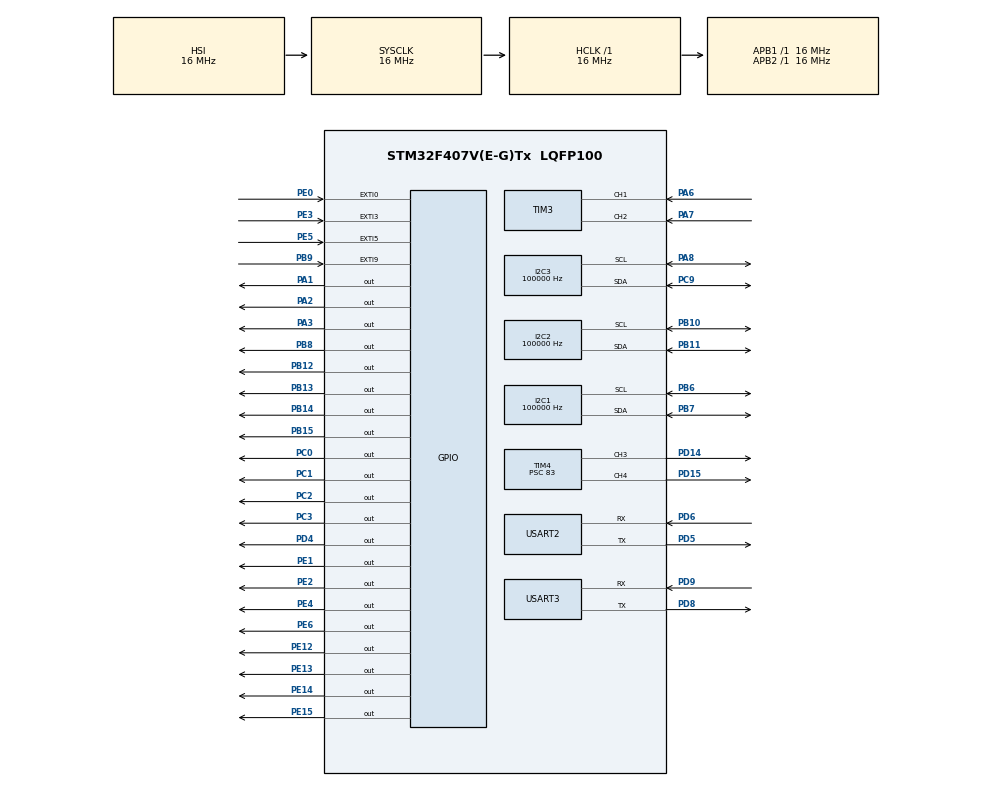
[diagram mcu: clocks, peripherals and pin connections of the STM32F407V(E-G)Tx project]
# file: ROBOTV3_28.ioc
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Dma.Request0=USART3_RX
Dma.Request1=USART3_TX
Dma.USART3_RX.0.Direction=DMA_PERIPH_TO_MEMORY
Dma.USART3_RX.0.FIFOMode=DMA_FIFOMODE_DISABLE
Dma.USART3_RX.0.Instance=DMA1_Stream1
Dma.USART3_RX.0.MemDataAlignment=DMA_MDATAALIGN_BYTE
Dma.USART3_RX.0.MemInc=DMA_MINC_ENABLE
Dma.USART3_RX.0.Mode=DMA_NORMAL
Dma.USART3_RX.0.PeriphDataAlignment=DMA_PDATAALIGN_BYTE
Dma.USART3_RX.0.PeriphInc=DMA_PINC_DISABLE
Dma.USART3_RX.0.Priority=DMA_PRIORITY_LOW
Dma.USART3_TX.1.Direction=DMA_MEMORY_TO_PERIPH
Dma.USART3_TX.1.FIFOMode=DMA_FIFOMODE_DISABLE
Dma.USART3_TX.1.Instance=DMA1_Stream4
Dma.USART3_TX.1.MemDataAlignment=DMA_MDATAALIGN_BYTE
Dma.USART3_TX.1.MemInc=DMA_MINC_ENABLE
Dma.USART3_TX.1.Mode=DMA_NORMAL
Dma.USART3_TX.1.PeriphDataAlignment=DMA_PDATAALIGN_BYTE
Dma.USART3_TX.1.PeriphInc=DMA_PINC_DISABLE
Dma.USART3_TX.1.Priority=DMA_PRIORITY_LOW
FREERTOS.BinarySemaphores01=Seme_Tx_dwin,Dynamic,NULL,Available;Theta_xyz,Dynamic,NULL,Available
FREERTOS.Queues01=Queue_DWIN,37,uint8_t,0,Dynamic,NULL,NULL
FREERTOS.Tasks01=Sensor_Task,24,128,Sensor_AS5600,Default,NULL,Dynamic,NULL,NULL;TaskHmi,8,128,Dwin_Task,Default,NULL,Dynamic,NULL,NULL;Task_DMA_HMI,25,128,TASK_DMA_ENTRY,Default,NULL,Dynamic,NULL,NULL;Task_controlmot,17,128,StartTask05,Default,NULL,Dynamic,NULL,NULL;Task_Dwin_get_t,26,128,StartTask06,Default,NULL,Dynamic,NULL,NULL
I2C1.ClockSpeed=100000
I2C1.I2C_Mode=I2C_Standard
I2C2.ClockSpeed=100000
I2C2.I2C_Mode=I2C_Standard
I2C3.ClockSpeed=100000
I2C3.I2C_Mode=I2C_Standard
Mcu.Family=STM32F4
Mcu.Name=STM32F407V(E-G)Tx
Mcu.Package=LQFP100
NVIC.DMA1_Stream1_IRQn=true\:5\:0\:false\:false\:true\:true\:false\:true\:true
NVIC.DMA1_Stream4_IRQn=true\:5\:0\:false\:false\:true\:true\:false\:true\:true
NVIC.EXTI9_5_IRQn=true\:7\:0\:true\:false\:true\:true\:true\:true\:true
NVIC.PriorityGroup=NVIC_PRIORITYGROUP_4
NVIC.TIM2_IRQn=true\:5\:0\:false\:false\:true\:true\:true\:true\:true
NVIC.TIM7_IRQn=true\:15\:0\:false\:false\:true\:false\:false\:true\:true
NVIC.TimeBase=TIM7_IRQn
NVIC.TimeBaseIP=TIM7
NVIC.USART3_IRQn=true\:5\:0\:true\:false\:true\:true\:true\:true\:true
PA1.GPIO_Speed=GPIO_SPEED_FREQ_VERY_HIGH
PA1.Signal=GPIO_Output
PA13.Mode=Serial_Wire
PA13.Signal=SYS_JTMS-SWDIO
PA14.Mode=Serial_Wire
PA14.Signal=SYS_JTCK-SWCLK
PA2.GPIO_Speed=GPIO_SPEED_FREQ_VERY_HIGH
PA2.Signal=GPIO_Output
PA3.GPIO_Speed=GPIO_SPEED_FREQ_VERY_HIGH
PA3.Signal=GPIO_Output
PA6.Signal=S_TIM3_CH1
PA7.Signal=S_TIM3_CH2
PA8.Mode=I2C
PA8.Signal=I2C3_SCL
PB10.Mode=I2C
PB10.Signal=I2C2_SCL
PB11.Mode=I2C
PB11.Signal=I2C2_SDA
PB12.Signal=GPIO_Output
PB13.Signal=GPIO_Output
PB14.Signal=GPIO_Output
PB15.Signal=GPIO_Output
PB6.Mode=I2C
PB6.Signal=I2C1_SCL
PB7.Mode=I2C
PB7.Signal=I2C1_SDA
PB8.Signal=GPIO_Output
PB9.GPIO_ModeDefaultEXTI=GPIO_MODE_IT_FALLING
PB9.Signal=GPXTI9
PC0.Signal=GPIO_Output
PC1.Signal=GPIO_Output
PC2.Signal=GPIO_Output
PC3.Signal=GPIO_Output
PC9.Mode=I2C
PC9.Signal=I2C3_SDA
PD14.Signal=S_TIM4_CH3
PD15.Signal=S_TIM4_CH4
PD4.Signal=GPIO_Output
PD5.Mode=Asynchronous
PD5.Signal=USART2_TX
PD6.Mode=Asynchronous
PD6.Signal=USART2_RX
PD8.Mode=Asynchronous
PD8.Signal=USART3_TX
PD9.Mode=Asynchronous
PD9.Signal=USART3_RX
PE0.GPIO_ModeDefaultEXTI=GPIO_MODE_IT_FALLING
PE0.Signal=GPXTI0
PE1.Signal=GPIO_Output
PE12.Signal=GPIO_Output
PE13.Signal=GPIO_Output
PE14.Signal=GPIO_Output
PE15.Signal=GPIO_Output
PE2.Signal=GPIO_Output
PE3.GPIO_ModeDefaultEXTI=GPIO_MODE_IT_FALLING
PE3.Signal=GPXTI3
PE4.Signal=GPIO_Output
PE5.GPIO_ModeDefaultEXTI=GPIO_MODE_IT_FALLING
PE5.Signal=GPXTI5
PE6.Signal=GPIO_Output
PH0-OSC_IN.Mode=HSE-External-Oscillator
PH0-OSC_IN.Signal=RCC_OSC_IN
PH1-OSC_OUT.Mode=HSE-External-Oscillator
PH1-OSC_OUT.Signal=RCC_OSC_OUT
ProjectManager.HeapSize=0x200
ProjectManager.StackSize=0x400
ProjectManager.TargetToolchain=STM32CubeIDE
RCC.AHBFreq_Value=16000000
RCC.APB1Freq_Value=16000000
RCC.APB2Freq_Value=16000000
RCC.CortexFreq_Value=16000000
RCC.HSE_VALUE=25000000
RCC.HSI_VALUE=16000000
RCC.LSE_VALUE=32768
RCC.SYSCLKFreq_VALUE=16000000
RCC.VCOOutputFreq_Value=192000000
SH.S_TIM3_CH1.0=TIM3_CH1,Encoder_Interface
SH.S_TIM3_CH2.0=TIM3_CH2,Encoder_Interface
SH.S_TIM4_CH3.0=TIM4_CH3,PWM Generation3 CH3
SH.S_TIM4_CH4.0=TIM4_CH4,PWM Generation4 CH4
TIM2.Period=99
TIM2.Prescaler=83
TIM4.Channel-PWM\ Generation3\ CH3=TIM_CHANNEL_3
TIM4.Channel-PWM\ Generation4\ CH4=TIM_CHANNEL_4
TIM4.Period=99
TIM4.Prescaler=83
USART2.VirtualMode=VM_ASYNC
USART3.VirtualMode=VM_ASYNC
VP_FREERTOS_VS_CMSIS_V2.Mode=CMSIS_V2
VP_SYS_VS_tim7.Mode=TIM7
VP_TIM2_VS_ClockSourceINT.Mode=Internal
board=custom

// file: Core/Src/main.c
/* USER CODE BEGIN Header */
/**
  ******************************************************************************
  * @file           : main.c
  * @brief          : Main program body
  ******************************************************************************
  * @attention
  *
  * Copyright (c) 2025 STMicroelectronics.
  * All rights reserved.
  *
  * This software is licensed under terms that can be found in the LICENSE file
  * in the root directory of this software component.
  * If no LICENSE file comes with this software, it is provided AS-IS.
  *
  ******************************************************************************
  */
/* USER CODE END Header */
#include "main.h"
#include "cmsis_os.h"
#include "dma.h"
#include "i2c.h"
#include "tim.h"
#include "usart.h"
#include "gpio.h"

/* USER CODE BEGIN Includes */
#include "alt_main.h"
/* USER CODE END Includes */

void SystemClock_Config(void);
void MX_FREERTOS_Init(void);

int main(void)
{

  /* MCU Configuration--------------------------------------------------------*/

  /* Reset of all peripherals, Initializes the Flash interface and the Systick. */
  HAL_Init();

  /* Configure the system clock */
  SystemClock_Config();

  /* USER CODE BEGIN SysInit */
  HAL_Delay(3000);//ỔN ĐỊNH MÀN HÌNH
  /* USER CODE END SysInit */

  /* Initialize all configured peripherals */
  MX_GPIO_Init();
  MX_DMA_Init();
  MX_I2C1_Init();
  MX_I2C2_Init();
  MX_I2C3_Init();
  MX_USART3_UART_Init();
  MX_TIM2_Init();
  MX_TIM4_Init();
  MX_USART2_UART_Init();
  MX_TIM3_Init();
  /* USER CODE BEGIN 2 */
  alt_main();
  /* USER CODE END 2 */

  /* Init scheduler */
  osKernelInitialize();

  /* Call init function for freertos objects (in cmsis_os2.c) */
  MX_FREERTOS_Init();

  /* Start scheduler */
  osKernelStart();

  /* We should never get here as control is now taken by the scheduler */

  /* Infinite loop */
  while (1)
  {

  }
}

void SystemClock_Config(void)
{
  RCC_OscInitTypeDef RCC_OscInitStruct = {0};
  RCC_ClkInitTypeDef RCC_ClkInitStruct = {0};

  /** Configure the main internal regulator output voltage
  */
  __HAL_RCC_PWR_CLK_ENABLE();
  __HAL_PWR_VOLTAGESCALING_CONFIG(PWR_REGULATOR_VOLTAGE_SCALE1);

  /** Initializes the RCC Oscillators according to the specified parameters
  * in the RCC_OscInitTypeDef structure.
  */
  RCC_OscInitStruct.OscillatorType = RCC_OSCILLATORTYPE_HSI;
  RCC_OscInitStruct.HSIState = RCC_HSI_ON;
  RCC_OscInitStruct.HSICalibrationValue = RCC_HSICALIBRATION_DEFAULT;
  RCC_OscInitStruct.PLL.PLLState = RCC_PLL_NONE;
  if (HAL_RCC_OscConfig(&RCC_OscInitStruct) != HAL_OK)
  {
    Error_Handler();
  }

  /** Initializes the CPU, AHB and APB buses clocks
  */
  RCC_ClkInitStruct.ClockType = RCC_CLOCKTYPE_HCLK|RCC_CLOCKTYPE_SYSCLK
                              |RCC_CLOCKTYPE_PCLK1|RCC_CLOCKTYPE_PCLK2;
  RCC_ClkInitStruct.SYSCLKSource = RCC_SYSCLKSOURCE_HSI;
  RCC_ClkInitStruct.AHBCLKDivider = RCC_SYSCLK_DIV1;
  RCC_ClkInitStruct.APB1CLKDivider = RCC_HCLK_DIV1;
  RCC_ClkInitStruct.APB2CLKDivider = RCC_HCLK_DIV1;

  if (HAL_RCC_ClockConfig(&RCC_ClkInitStruct, FLASH_LATENCY_0) != HAL_OK)
  {
    Error_Handler();
  }
}

void HAL_TIM_PeriodElapsedCallback(TIM_HandleTypeDef *htim)
{
  if (htim->Instance == TIM7) {
    HAL_IncTick();
  }
  /* USER CODE BEGIN Callback 1 */
  if (htim->Instance == TIM2){
	  TIM2_CALLBACK_STEP();
  }
  /* USER CODE END Callback 1 */
}

void Error_Handler(void)
{
  __disable_irq();
  while (1)
  {
  }
}

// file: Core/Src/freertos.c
/* USER CODE BEGIN Header */
/**
  ******************************************************************************
  * File Name          : freertos.c
  * Description        : Code for freertos applications
  ******************************************************************************
  * @attention
  *
  * Copyright (c) 2025 STMicroelectronics.
  * All rights reserved.
  *
  * This software is licensed under terms that can be found in the LICENSE file
  * in the root directory of this software component.
  * If no LICENSE file comes with this software, it is provided AS-IS.
  *
  ******************************************************************************
  */
/* USER CODE END Header */

#include "FreeRTOS.h"
#include "task.h"
#include "main.h"
#include "cmsis_os.h"

/* USER CODE BEGIN Includes */
#include "alt_main.h"
/* USER CODE END Includes */

/* Definitions for Sensor_Task */
osThreadId_t Sensor_TaskHandle;
const osThreadAttr_t Sensor_Task_attributes = {
  .name = "Sensor_Task",
  .stack_size = 128 * 4,
  .priority = (osPriority_t) osPriorityNormal,
};
/* Definitions for TaskHmi */
osThreadId_t TaskHmiHandle;
const osThreadAttr_t TaskHmi_attributes = {
  .name = "TaskHmi",
  .stack_size = 128 * 4,
  .priority = (osPriority_t) osPriorityLow,
};
/* Definitions for Task_DMA_HMI */
osThreadId_t Task_DMA_HMIHandle;
const osThreadAttr_t Task_DMA_HMI_attributes = {
  .name = "Task_DMA_HMI",
  .stack_size = 128 * 4,
  .priority = (osPriority_t) osPriorityNormal1,
};
/* Definitions for Task_controlmot */
osThreadId_t Task_controlmotHandle;
const osThreadAttr_t Task_controlmot_attributes = {
  .name = "Task_controlmot",
  .stack_size = 128 * 4,
  .priority = (osPriority_t) osPriorityBelowNormal1,
};
/* Definitions for Task_Dwin_get_t */
osThreadId_t Task_Dwin_get_tHandle;
const osThreadAttr_t Task_Dwin_get_t_attributes = {
  .name = "Task_Dwin_get_t",
  .stack_size = 128 * 4,
  .priority = (osPriority_t) osPriorityNormal2,
};
/* Definitions for Queue_DWIN */
osMessageQueueId_t Queue_DWINHandle;
const osMessageQueueAttr_t Queue_DWIN_attributes = {
  .name = "Queue_DWIN"
};
/* Definitions for Seme_Tx_dwin */
osSemaphoreId_t Seme_Tx_dwinHandle;
const osSemaphoreAttr_t Seme_Tx_dwin_attributes = {
  .name = "Seme_Tx_dwin"
};
/* Definitions for Theta_xyz */
osSemaphoreId_t Theta_xyzHandle;
const osSemaphoreAttr_t Theta_xyz_attributes = {
  .name = "Theta_xyz"
};

void Sensor_AS5600(void *argument);
void Dwin_Task(void *argument);
void TASK_DMA_ENTRY(void *argument);
void StartTask05(void *argument);
void StartTask06(void *argument);

void MX_FREERTOS_Init(void); /* (MISRA C 2004 rule 8.1) */

void MX_FREERTOS_Init(void) {

  /* Create the semaphores(s) */
  /* creation of Seme_Tx_dwin */
  Seme_Tx_dwinHandle = osSemaphoreNew(1, 1, &Seme_Tx_dwin_attributes);

  /* creation of Theta_xyz */
  Theta_xyzHandle = osSemaphoreNew(1, 0, &Theta_xyz_attributes);

  /* Create the queue(s) */
  /* creation of Queue_DWIN */
  Queue_DWINHandle = osMessageQueueNew (37, sizeof(uint8_t), &Queue_DWIN_attributes);

  /* Create the thread(s) */
  /* creation of Sensor_Task */
  Sensor_TaskHandle = osThreadNew(Sensor_AS5600, NULL, &Sensor_Task_attributes);

  /* creation of TaskHmi */
  TaskHmiHandle = osThreadNew(Dwin_Task, NULL, &TaskHmi_attributes);

  /* creation of Task_DMA_HMI */
  Task_DMA_HMIHandle = osThreadNew(TASK_DMA_ENTRY, NULL, &Task_DMA_HMI_attributes);

  /* creation of Task_controlmot */
  Task_controlmotHandle = osThreadNew(StartTask05, NULL, &Task_controlmot_attributes);

  /* creation of Task_Dwin_get_t */
  Task_Dwin_get_tHandle = osThreadNew(StartTask06, NULL, &Task_Dwin_get_t_attributes);

}

void Sensor_AS5600(void *argument)
{
  /* USER CODE BEGIN Sensor_AS5600 */
  /* Infinite loop */
	Sensor_AS5600_RTOS();
//  for(;;)
//  {
//    osDelay(1);
//  }
  /* USER CODE END Sensor_AS5600 */
}

void Dwin_Task(void *argument)
{
  /* USER CODE BEGIN Dwin_Task */
  /* Infinite loop */
	Dwin_RTOS();
//  for(;;)
//  {
//    osDelay(1);
//  }
  /* USER CODE END Dwin_Task */
}

void TASK_DMA_ENTRY(void *argument)
{
  /* USER CODE BEGIN TASK_DMA_ENTRY */
  /* Infinite loop */
	DwinUsartTask_RTOS();
//  for(;;)
//  {
//    osDelay(1);
//  }
  /* USER CODE END TASK_DMA_ENTRY */
}

void StartTask05(void *argument)
{
  /* USER CODE BEGIN StartTask05 */
  /* Infinite loop */
	Control_motor_RTOS();
//  for(;;)
//  {
//    osDelay(1);
//  }
  /* USER CODE END StartTask05 */
}

void StartTask06(void *argument)
{
  /* USER CODE BEGIN StartTask06 */
  /* Infinite loop */
	Control_Dwin_get_theta_RTOS();
//  for(;;)
//  {
//    osDelay(1);
//  }
  /* USER CODE END StartTask06 */
}
